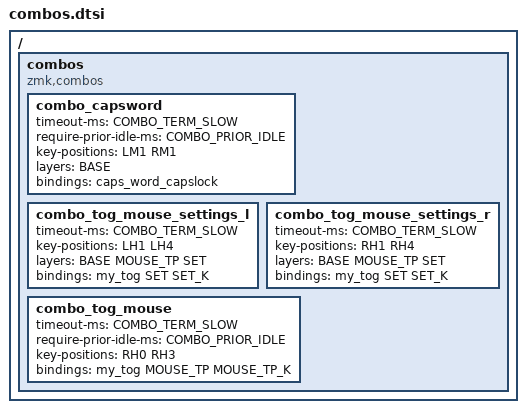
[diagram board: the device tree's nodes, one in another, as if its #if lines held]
#define COMBO_TERM_FAST 35
#define COMBO_TERM_SLOW 40
#define COMBO_PRIOR_IDLE 100

/ {
  combos {
    compatible = "zmk,combos";


    combo_capsword {
      timeout-ms = <COMBO_TERM_SLOW>;
      require-prior-idle-ms = <COMBO_PRIOR_IDLE>;
      key-positions = <LM1 RM1>;
      layers = <BASE>;

#ifdef HAS_CAPSLOCK
      bindings = <&caps_word_capslock >;
#else
      bindings = <&caps_word>;
#endif
    };

    //  combo_return {
    //    timeout-ms = <COMBO_TERM_FAST>;
    //    require-prior-idle-ms = <COMBO_PRIOR_IDLE>;
    //    key-positions = <LH2 LH1 LH0>;
    //    layers = <BASE NAV NUM SYM>;
    //    bindings = <&kp RET>;
    //  };

    //  combo_bspc {
    //    timeout-ms = <COMBO_TERM_FAST>;
    //    require-prior-idle-ms = <COMBO_PRIOR_IDLE>;
    //    key-positions = <LH1 LH0>;
    //    layers = <BASE NAV NUM SYM>;
    //    bindings = <&kp BSPC>;
    //  };

    // combo_grave {
    //   timeout-ms = <COMBO_TERM_SLOW>;
    //   require-prior-idle-ms = <COMBO_PRIOR_IDLE>;
    //   key-positions = <RM3 RM4>;
    //   layers = <>;
    //   bindings = <&kp GRAVE>;
    // };

    // combo_md_code_block {
    //   timeout-ms = <COMBO_TERM_SLOW>;
    //   require-prior-idle-ms = <COMBO_PRIOR_IDLE>;
    //   key-positions = <RM2 RM3 RM4>;
    //   layers = <>;
    //   bindings = <&m_type_md_code_block>;
    // };

  //  combo_tog_nav_word {
  //    timeout-ms = <COMBO_TERM_SLOW>;
  //    require-prior-idle-ms = <COMBO_PRIOR_IDLE>;
  //    key-positions = <LM3 LM2 LM1>;
  //    layers = <BASE NUM NUM_WORD>;
  //
  //    #ifdef HAS_UROB
  //      bindings = <&nav_word>;
  //    #else
  //      bindings = <&tog NAV_WORD>;
  //    #endif
  //
  //  };

  //  combo_tog_num_word {
  //    timeout-ms = <COMBO_TERM_SLOW>;
  //    require-prior-idle-ms = <COMBO_PRIOR_IDLE>;
  //    key-positions = <LB3 LB2 LB1>;
  //    layers = <BASE NAV NAV_WORD>;
//
  //    #ifdef HAS_UROB
  //      bindings = <&num_word>;
  //    #else
  //      bindings = <&tog NUM_WORD>;
  //    #endif
//
  //  };

#ifdef HAS_MOUSE_TP
    combo_tog_mouse_settings_l {
      timeout-ms = <COMBO_TERM_SLOW>;
      // require-prior-idle-ms = <COMBO_PRIOR_IDLE>;
      key-positions = <LH1 LH4>;
      layers = <BASE MOUSE_TP SET>;
      bindings = <&my_tog SET SET_K>;
    };

    combo_tog_mouse_settings_r {
      timeout-ms = <COMBO_TERM_SLOW>;
      // require-prior-idle-ms = <COMBO_PRIOR_IDLE>;
      key-positions = <RH1 RH4>;
      layers = <BASE MOUSE_TP SET>;
      bindings = <&my_tog SET SET_K>;
    };

    combo_tog_mouse {
      timeout-ms = <COMBO_TERM_SLOW>;
      require-prior-idle-ms = <COMBO_PRIOR_IDLE>;
      key-positions = <RH0 RH3>;
      // layers = <BASE MOUSE_TP>;
      bindings = <&my_tog MOUSE_TP MOUSE_TP_K>;
    };
#endif



//#ifdef HAS_MOUSE_KEYS
//    combo_tog_mouse_keys_l {
//      timeout-ms = <COMBO_TERM_SLOW>;
//      // require-prior-idle-ms = <COMBO_PRIOR_IDLE>;
//      key-positions = <LM2 LM3 LM4>;
//      layers = <BASE NAV NAV_WORD MOUSE_KEYS>;
//      bindings = <&tog MOUSE_KEYS>;
//    };
//
//    combo_tog_mouse_keys_r {
//      timeout-ms = <COMBO_TERM_SLOW>;
//      // require-prior-idle-ms = <COMBO_PRIOR_IDLE>;
//      key-positions = <RM2 RM3 RM4>;
//      layers = <BASE NAV NAV_WORD MOUSE_KEYS>;
//      bindings = <&tog MOUSE_KEYS>;
//    };
//#endif

  };
};
